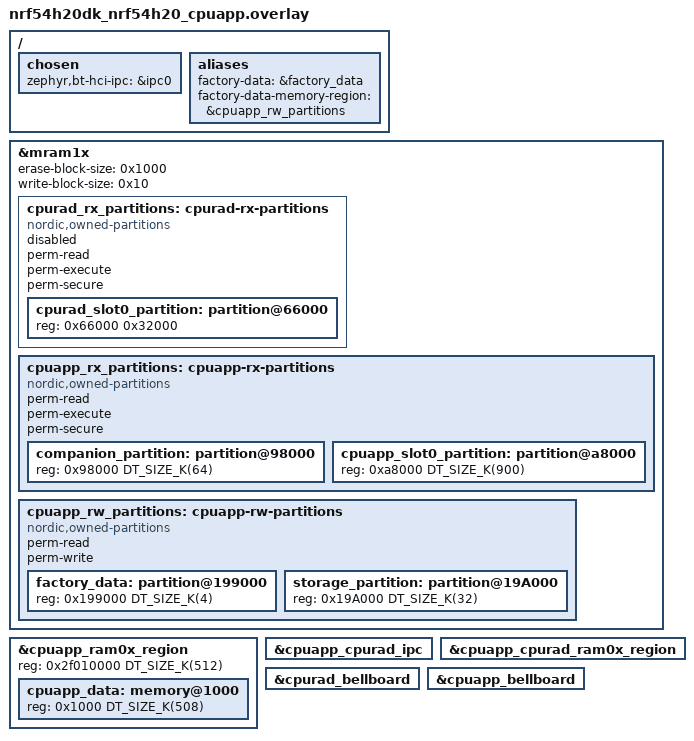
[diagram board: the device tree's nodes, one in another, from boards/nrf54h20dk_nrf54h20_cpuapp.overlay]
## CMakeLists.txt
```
#
# Copyright (c) 2021 Nordic Semiconductor ASA
#
# SPDX-License-Identifier: LicenseRef-Nordic-5-Clause
#

cmake_minimum_required(VERSION 3.20.0)

find_package(Zephyr HINTS $ENV{ZEPHYR_BASE})

project(matter-template)

# Enable GNU STD support.
include(${ZEPHYR_CONNECTEDHOMEIP_MODULE_DIR}/config/nrfconnect/app/enable-gnu-std.cmake)

# NORDIC SDK APP START

# Include all source files that are located in the Matter common directory.
include(${ZEPHYR_NRF_MODULE_DIR}/samples/matter/common/cmake/source_common.cmake)

# Include Data Model utils
include(${ZEPHYR_NRF_MODULE_DIR}/samples/matter/common/cmake/data_model.cmake)

target_include_directories(app PRIVATE
    src
    ${CONFIG_NCS_SAMPLE_MATTER_ZAP_FILES_PATH}
)

target_sources(app PRIVATE
    src/main.cpp
)

if("thread-platform" IN_LIST SNIPPET)
  target_sources(app PRIVATE 
    snippets/thread_platform/app_task.cpp
    snippets/thread_platform/zcl_callbacks.cpp
  )
  target_include_directories(app PRIVATE 
    snippets/thread_platform
  )
else()
  target_sources(app PRIVATE 
    src/app_task.cpp
  )
endif()

ncs_configure_data_model(
    ZAP_FILE ${CMAKE_CURRENT_SOURCE_DIR}/${CONFIG_NCS_SAMPLE_MATTER_ZAP_FILES_PATH}/template.zap
)
# NORDIC SDK APP END
```

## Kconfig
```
#
# Copyright (c) 2022 Nordic Semiconductor
#
# SPDX-License-Identifier: LicenseRef-Nordic-5-Clause
#
mainmenu "Matter nRF Connect Template Example Application"

# Sample configuration used for Thread networking
if OPENTHREAD

choice OPENTHREAD_NORDIC_LIBRARY_CONFIGURATION
	default OPENTHREAD_NORDIC_LIBRARY_MTD
endchoice

choice OPENTHREAD_DEVICE_TYPE
	default OPENTHREAD_MTD
endchoice

# SED with 0 dBm Thread TX output power for nRF54L15 tag
if BOARD_NRF54L15TAG

configdefault CHIP_ENABLE_ICD_SUPPORT
	default y

configdefault OPENTHREAD_DEFAULT_TX_POWER
	default 0

endif

endif # OPENTHREAD

configdefault CHIP_WIFI
	default y if SHIELD_NRF7002EB2

source "$(ZEPHYR_CONNECTEDHOMEIP_MODULE_DIR)/config/nrfconnect/chip-module/Kconfig.features"
source "$(ZEPHYR_CONNECTEDHOMEIP_MODULE_DIR)/config/nrfconnect/chip-module/Kconfig.defaults"
source "$(ZEPHYR_NRF_MODULE_DIR)/samples/matter/common/src/Kconfig"
source "Kconfig.zephyr"
```

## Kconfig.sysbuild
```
#
# Copyright (c) 2023 Nordic Semiconductor ASA
#
# SPDX-License-Identifier: LicenseRef-Nordic-5-Clause
#

# This config has to be enabled manually for variants with shields, because sysbuild does not support it.
config WIFI_NRF70
	default y if BOARD_NRF7002DK

#### Radio core selection
config NRF_DEFAULT_IPC_RADIO
	default y

# Enable IEEE802.15.4 serialization to network core
# This config automatically pulls in the `overlay-802154.conf` in the ipc_radio image
config NETCORE_IPC_RADIO_IEEE802154
	default y if SOC_SERIES_NRF53 && !WIFI_NRF70

# Enable Bluetooth serialization to network core
# This config automatically pulls in the `overlay-bt_hci_ipc.conf` in the ipc_radio image
config NETCORE_IPC_RADIO_BT_HCI_IPC
	default y if SOC_SERIES_NRF53

#### Bootloader
choice BOOTLOADER
	default BOOTLOADER_MCUBOOT if !BOARD_NRF21540DK
endchoice

if BOOTLOADER_MCUBOOT

#### DFU multi-image support
config DFU_MULTI_IMAGE_PACKAGE_BUILD
	default y

config DFU_MULTI_IMAGE_PACKAGE_APP
	default y

#### DFU network core configuration
if SOC_SERIES_NRF53

choice MCUBOOT_MODE
	default MCUBOOT_MODE_OVERWRITE_ONLY
endchoice

choice BOOT_SIGNATURE_TYPE
	default BOOT_SIGNATURE_TYPE_RSA
endchoice

config SECURE_BOOT_NETCORE
	default y

config NETCORE_APP_UPDATE
	default y

config DFU_MULTI_IMAGE_PACKAGE_NET
	default y

endif # SOC_SERIES_NRF53
endif # BOOTLOADER_MCUBOOT

# Store the Wi-Fi firmware patch on external flash by default for nRF5340 with nRF7002
if WIFI_NRF70 && SOC_NRF5340_CPUAPP

choice WIFI_PATCHES_EXT_FLASH_SUPPORT
	default WIFI_PATCHES_EXT_FLASH_STORE

endchoice

config DFU_MULTI_IMAGE_PACKAGE_WIFI_FW_PATCH
	default y

endif # WIFI_NRF70

#### Enable generating factory data
config MATTER_FACTORY_DATA_GENERATE
	default y if !BOARD_NRF21540DK

# Internal flash only for nRF54L15 tag with compression
if BOARD_NRF54L15TAG

choice MCUBOOT_MODE
	default MCUBOOT_MODE_OVERWRITE_ONLY
endchoice

config MCUBOOT_COMPRESSED_IMAGE_SUPPORT
	default y

endif

source "share/sysbuild/Kconfig"
```

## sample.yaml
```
sample:
  description: Matter Template sample
  name: Matter Template
common:
  tags:
    - sysbuild
    - ci_samples_matter
tests:
  sample.matter.template.debug:
    sysbuild: true
    build_only: true
    extra_args:
      - CONFIG_NCS_SAMPLE_MATTER_OPERATIONAL_KEYS_MIGRATION_TO_ITS=y
    integration_platforms:
      - nrf52840dk/nrf52840
      - nrf5340dk/nrf5340/cpuapp
      - nrf54l15dk/nrf54l15/cpuapp
      - nrf54l15dk/nrf54l10/cpuapp
      - nrf54l15tag/nrf54l15/cpuapp
      - nrf54lm20dk/nrf54lm20b/cpuapp
      - nrf54lm20dk/nrf54lm20a/cpuapp
    platform_allow:
      - nrf52840dk/nrf52840
      - nrf5340dk/nrf5340/cpuapp
      - nrf54l15dk/nrf54l15/cpuapp
      - nrf54l15dk/nrf54l15/cpuapp/ns
      - nrf54l15dk/nrf54l10/cpuapp
      - nrf54l15tag/nrf54l15/cpuapp
      - nrf54lm20dk/nrf54lm20b/cpuapp
      - nrf54lm20dk/nrf54lm20a/cpuapp
  sample.matter.template.nrf7002eb2.debug:
    sysbuild: true
    build_only: true
    extra_args:
      - template_SHIELD=nrf7002eb2
      - SB_CONFIG_WIFI_NRF70=y
    integration_platforms:
      - nrf54lm20dk/nrf54lm20b/cpuapp
      - nrf54lm20dk/nrf54lm20a/cpuapp
    platform_allow:
      - nrf54lm20dk/nrf54lm20b/cpuapp
      - nrf54lm20dk/nrf54lm20a/cpuapp
  sample.matter.template.release:
    sysbuild: true
    build_only: true
    extra_args:
      - FILE_SUFFIX=release
      - CONFIG_NCS_SAMPLE_MATTER_OPERATIONAL_KEYS_MIGRATION_TO_ITS=y
    integration_platforms:
      - nrf52840dk/nrf52840
      - nrf5340dk/nrf5340/cpuapp
      - nrf54l15dk/nrf54l15/cpuapp
      - nrf54l15dk/nrf54l10/cpuapp
      - nrf54l15tag/nrf54l15/cpuapp
      - nrf54lm20dk/nrf54lm20b/cpuapp
      - nrf54lm20dk/nrf54lm20a/cpuapp
    platform_allow:
      - nrf52840dk/nrf52840
      - nrf5340dk/nrf5340/cpuapp
      - nrf54l15dk/nrf54l15/cpuapp
      - nrf54l15dk/nrf54l10/cpuapp
      - nrf54l15tag/nrf54l15/cpuapp
      - nrf54lm20dk/nrf54lm20b/cpuapp
      - nrf54lm20dk/nrf54lm20a/cpuapp
  sample.matter.template.nrf7002eb2.release:
    sysbuild: true
    build_only: true
    extra_args:
      - FILE_SUFFIX=release
      - template_SHIELD=nrf7002eb2
      - SB_CONFIG_WIFI_NRF70=y
    integration_platforms:
      - nrf54lm20dk/nrf54lm20b/cpuapp
      - nrf54lm20dk/nrf54lm20a/cpuapp
    platform_allow:
      - nrf54lm20dk/nrf54lm20b/cpuapp
      - nrf54lm20dk/nrf54lm20a/cpuapp
  sample.matter.template.smp_dfu:
    sysbuild: true
    build_only: true
    extra_args:
      - CONFIG_CHIP_DFU_OVER_BT_SMP=y
      - CONFIG_NCS_SAMPLE_MATTER_OPERATIONAL_KEYS_MIGRATION_TO_ITS=y
    integration_platforms:
      - nrf54l15dk/nrf54l15/cpuapp
      - nrf54l15dk/nrf54l10/cpuapp
      - nrf54l15tag/nrf54l15/cpuapp
      - nrf54lm20dk/nrf54lm20b/cpuapp
      - nrf54lm20dk/nrf54lm20a/cpuapp
    platform_allow:
      - nrf52840dk/nrf52840
      - nrf5340dk/nrf5340/cpuapp
      - nrf54l15dk/nrf54l15/cpuapp
      - nrf54l15dk/nrf54l10/cpuapp
      - nrf54l15tag/nrf54l15/cpuapp
      - nrf54lm20dk/nrf54lm20b/cpuapp
      - nrf54lm20dk/nrf54lm20a/cpuapp
  sample.matter.template.tfm:
    sysbuild: true
    build_only: true
    extra_args:
      - FILE_SUFFIX=tfm
      - CONFIG_CHIP_DFU_OVER_BT_SMP=y
    integration_platforms:
      - nrf54l15dk/nrf54l15/cpuapp/ns
    platform_allow:
      - nrf54l15dk/nrf54l15/cpuapp/ns
  sample.matter.template.nrf7002eb2.smp_dfu:
    sysbuild: true
    build_only: true
    extra_args:
      - CONFIG_CHIP_DFU_OVER_BT_SMP=y
      - template_SHIELD=nrf7002eb2
      - SB_CONFIG_WIFI_NRF70=y
    integration_platforms:
      - nrf54lm20dk/nrf54lm20b/cpuapp
      - nrf54lm20dk/nrf54lm20a/cpuapp
    platform_allow:
      - nrf54lm20dk/nrf54lm20b/cpuapp
      - nrf54lm20dk/nrf54lm20a/cpuapp
  sample.matter.template.release.internal:
    sysbuild: true
    build_only: true
    extra_args:
      - FILE_SUFFIX=internal
      - template_EXTRA_CONF_FILE=prj_release.conf
    integration_platforms:
      - nrf54l15dk/nrf54l15/cpuapp
      - nrf54lm20dk/nrf54lm20b/cpuapp
      - nrf54lm20dk/nrf54lm20a/cpuapp
    platform_allow:
      - nrf54l15dk/nrf54l15/cpuapp
      - nrf54lm20dk/nrf54lm20b/cpuapp
      - nrf54lm20dk/nrf54lm20a/cpuapp
  sample.matter.template.nrf7002eb2.release.internal:
    sysbuild: true
    build_only: true
    extra_args:
      - FILE_SUFFIX=internal
      - template_EXTRA_CONF_FILE=prj_release.conf
      - template_SHIELD=nrf7002eb2
      - SB_CONFIG_WIFI_NRF70=y
    integration_platforms:
      - nrf54lm20dk/nrf54lm20b/cpuapp
      - nrf54lm20dk/nrf54lm20a/cpuapp
    platform_allow:
      - nrf54lm20dk/nrf54lm20b/cpuapp
      - nrf54lm20dk/nrf54lm20a/cpuapp
  sample.matter.template.release.internal.smp_dfu:
    sysbuild: true
    build_only: true
    extra_args:
      - FILE_SUFFIX=internal
      - CONFIG_CHIP_DFU_OVER_BT_SMP=y
      - template_EXTRA_CONF_FILE=prj_release.conf
    integration_platforms:
      - nrf54l15dk/nrf54l15/cpuapp
      - nrf54lm20dk/nrf54lm20b/cpuapp
      - nrf54lm20dk/nrf54lm20a/cpuapp
    platform_allow:
      - nrf54l15dk/nrf54l15/cpuapp
      - nrf54lm20dk/nrf54lm20b/cpuapp
      - nrf54lm20dk/nrf54lm20a/cpuapp
  sample.matter.template.nrf7002eb2.release.internal.smp_dfu:
    sysbuild: true
    build_only: true
    extra_args:
      - FILE_SUFFIX=internal
      - CONFIG_CHIP_DFU_OVER_BT_SMP=y
      - template_EXTRA_CONF_FILE=prj_release.conf
      - template_SHIELD=nrf7002eb2
      - SB_CONFIG_WIFI_NRF70=y
    integration_platforms:
      - nrf54lm20dk/nrf54lm20b/cpuapp
      - nrf54lm20dk/nrf54lm20a/cpuapp
    platform_allow:
      - nrf54lm20dk/nrf54lm20b/cpuapp
      - nrf54lm20dk/nrf54lm20a/cpuapp
  sample.matter.template.cc3xx_backend:
    sysbuild: true
    build_only: true
    extra_args:
      - CONFIG_PSA_CRYPTO_DRIVER_CC3XX=y
    integration_platforms:
      - nrf52840dk/nrf52840
      - nrf5340dk/nrf5340/cpuapp
    platform_allow:
      - nrf52840dk/nrf52840
      - nrf5340dk/nrf5340/cpuapp
  sample.matter.template.smp_dfu.old_ec:
    sysbuild: true
    build_only: true
    extra_args:
      - CONFIG_CHIP_DFU_OVER_BT_SMP=y
      - SB_CONFIG_BOOT_SIGNATURE_TYPE_RSA=y
      - CONFIG_SETTINGS_ZMS_LEGACY=y
    integration_platforms:
      - nrf54l15dk/nrf54l15/cpuapp
    platform_allow:
      - nrf54l15dk/nrf54l15/cpuapp
  sample.matter.template.certification:
    sysbuild: true
    build_only: true
    extra_args:
      - CONFIG_NCS_SAMPLE_MATTER_CERTIFICATION=y
      - OVERLAY_CONFIG="../common/src/certification/thread_platform/overlay-thread_platform.conf"
      - template_SNIPPET="matter-diagnostic-logs;matter-debug"
    integration_platforms:
      - nrf52840dk/nrf52840
      - nrf5340dk/nrf5340/cpuapp
      - nrf54l15dk/nrf54l15/cpuapp
      - nrf54lm20dk/nrf54lm20b/cpuapp
      - nrf54lm20dk/nrf54lm20a/cpuapp
    platform_allow:
      - nrf52840dk/nrf52840
      - nrf5340dk/nrf5340/cpuapp
      - nrf54l15dk/nrf54l15/cpuapp
      - nrf54lm20dk/nrf54lm20b/cpuapp
      - nrf54lm20dk/nrf54lm20a/cpuapp
```

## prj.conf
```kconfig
#
# Copyright (c) 2021 Nordic Semiconductor ASA
#
# SPDX-License-Identifier: LicenseRef-Nordic-5-Clause
#

# This sample uses Kconfig.defaults to set options common for all
# samples. This file should contain only options specific for this sample
# or overrides of default values.

# Enable CHIP
CONFIG_CHIP=y
CONFIG_CHIP_PROJECT_CONFIG="src/chip_project_config.h"

# Configure ZAP file name
CONFIG_NCS_SAMPLE_MATTER_ZAP_FILE_NAME="template.zap"

# 32768 == 0x8000 (example Product ID added temporaly,
# but it must be changed with proper PID from the list:
# https://github.com/project-chip/connectedhomeip/blob/482e6fd03196a6de45465a90003947ef4b86e0b1/docs/examples/discussion/PID_allocation_for_example_apps.md)
CONFIG_CHIP_DEVICE_PRODUCT_ID=32768
CONFIG_STD_CPP17=y

# Enable Matter pairing automatically on application start.
CONFIG_CHIP_ENABLE_PAIRING_AUTOSTART=y

# Enable Matter extended announcement and increase duration to 1 hour.
CONFIG_CHIP_BLE_EXT_ADVERTISING=y
CONFIG_CHIP_BLE_ADVERTISING_DURATION=60

# Add support for LEDs and buttons on Nordic development kits
CONFIG_DK_LIBRARY=y

# Bluetooth Low Energy configuration
CONFIG_BT_DEVICE_NAME="MatterTemplate"

# Other settings
CONFIG_THREAD_NAME=y
CONFIG_MPU_STACK_GUARD=y
CONFIG_RESET_ON_FATAL_ERROR=n
CONFIG_CHIP_LIB_SHELL=y
CONFIG_NCS_SAMPLE_MATTER_TEST_SHELL=y

# Disable NFC commissioning
CONFIG_CHIP_NFC_ONBOARDING_PAYLOAD=n

# Reduce application size
CONFIG_USE_SEGGER_RTT=n

# Enable Factory Data feature
CONFIG_CHIP_FACTORY_DATA=y
CONFIG_CHIP_FACTORY_DATA_BUILD=y
```

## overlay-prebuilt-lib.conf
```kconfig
# Use the prebuilt Matter stack library from the Matter module lib/ directory.
CONFIG_CHIP_USE_PREBUILT_LIB=y
```

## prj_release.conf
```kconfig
#
# Copyright (c) 2021 Nordic Semiconductor ASA
#
# SPDX-License-Identifier: LicenseRef-Nordic-5-Clause
#

# This sample uses Kconfig.defaults to set options common for all
# samples. This file should contain only options specific for this sample
# or overrides of default values.

# Enable CHIP
CONFIG_CHIP=y
CONFIG_CHIP_PROJECT_CONFIG="src/chip_project_config.h"
# 32768 == 0x8000 (example Product ID added temporaly,
# but it must be changed with proper PID from the list:
# https://github.com/project-chip/connectedhomeip/blob/482e6fd03196a6de45465a90003947ef4b86e0b1/docs/examples/discussion/PID_allocation_for_example_apps.md)
CONFIG_CHIP_DEVICE_PRODUCT_ID=32768
CONFIG_STD_CPP17=y

# Enable Matter pairing automatically on application start.
CONFIG_CHIP_ENABLE_PAIRING_AUTOSTART=y

# Enable Matter extended announcement and increase duration to 1 hour.
CONFIG_CHIP_BLE_EXT_ADVERTISING=y
CONFIG_CHIP_BLE_ADVERTISING_DURATION=60

# Add support for LEDs and buttons on Nordic development kits
CONFIG_DK_LIBRARY=y

# Bluetooth Low Energy configuration
CONFIG_BT_DEVICE_NAME="MatterTemplate"

# Enable system reset on fatal error
CONFIG_RESET_ON_FATAL_ERROR=y

# Disable all debug features
CONFIG_USE_SEGGER_RTT=n
CONFIG_SHELL=n
CONFIG_OPENTHREAD_SHELL=n
CONFIG_CHIP_LIB_SHELL=n
CONFIG_CONSOLE=n
CONFIG_UART_CONSOLE=n
CONFIG_SERIAL=n
CONFIG_LOG=n
CONFIG_LOG_MODE_MINIMAL=n
CONFIG_ASSERT_VERBOSE=n
CONFIG_ASSERT_NO_FILE_INFO=y
CONFIG_PRINTK=n
CONFIG_PRINTK_SYNC=n
CONFIG_THREAD_NAME=n
CONFIG_BOOT_BANNER=n

# Disable NFC commissioning
CONFIG_CHIP_NFC_COMMISSIONING=n

# Enable Factory Data feature
CONFIG_CHIP_FACTORY_DATA=y
CONFIG_CHIP_FACTORY_DATA_BUILD=y

# Enable Watchdog
CONFIG_NCS_MATTER_WATCHDOG=y

# Enable LTO to decrease the flash usage.
CONFIG_LTO=y
CONFIG_ISR_TABLES_LOCAL_DECLARATION=y
```

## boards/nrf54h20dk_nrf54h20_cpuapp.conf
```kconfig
#
# Copyright (c) 2024 Nordic Semiconductor ASA
#
# SPDX-License-Identifier: LicenseRef-Nordic-5-Clause
#

# TODO: Workaround to be removed once DFU and external flash will be supported on nRF54H20.
CONFIG_CHIP_QSPI_NOR=n

CONFIG_MPU_STACK_GUARD=n

# TODO: Enable PSA crypto once it is available
CONFIG_CHIP_CRYPTO_PSA=n
CONFIG_MBEDTLS_CIPHER_PADDING_PKCS7=y
CONFIG_MBEDTLS_CIPHER_MODE_CBC=y

# TODO: Enable factory data once it is available
CONFIG_CHIP_FACTORY_DATA=n

# TODO: Workaround to be removed once Zephyr's CONFIG_FPROTECT is supported on nRF54H20.
CONFIG_CHIP_FACTORY_DATA_WRITE_PROTECT=n

# Set SUIT template paths
CONFIG_SUIT_ENVELOPE_TEMPLATE="../common/suit_templates/app_envelope.yaml.jinja2"
```

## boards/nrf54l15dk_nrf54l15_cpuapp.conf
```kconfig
#
# Copyright (c) 2024 Nordic Semiconductor ASA
#
# SPDX-License-Identifier: LicenseRef-Nordic-5-Clause
#

# Multirole is the only currently supported role by SoftDevice.
CONFIG_BT_LL_SOFTDEVICE_MULTIROLE=y

# ZMS cache optimization
CONFIG_ZMS_LOOKUP_CACHE=y
CONFIG_ZMS_LOOKUP_CACHE_SIZE=512
CONFIG_ZMS_LOOKUP_CACHE_FOR_SETTINGS=y

# Workaround required as Zephyr L2 implies usage of NVS backend for settings.
# It should be removed once the proper fix will be applied in Zephyr.
CONFIG_NVS=n

# Enable KMU support
CONFIG_OPENTHREAD_PSA_NVM_BACKEND_KMU=y 
CONFIG_CHIP_STORE_KEYS_IN_KMU=y
```

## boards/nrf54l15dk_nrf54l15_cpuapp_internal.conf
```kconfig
#
# Copyright (c) 2024 Nordic Semiconductor ASA
#
# SPDX-License-Identifier: LicenseRef-Nordic-5-Clause
#

# Multirole is the only currently supported role by SoftDevice.
CONFIG_BT_LL_SOFTDEVICE_MULTIROLE=y

# ZMS cache optimization
CONFIG_ZMS_LOOKUP_CACHE=y
CONFIG_ZMS_LOOKUP_CACHE_SIZE=512
CONFIG_ZMS_LOOKUP_CACHE_FOR_SETTINGS=y

# Workaround required as Zephyr L2 implies usage of NVS backend for settings.
# It should be removed once the proper fix will be applied in Zephyr.
CONFIG_NVS=n

# Disable SPI
CONFIG_CHIP_SPI_NOR=n

# Enable Watchdog
CONFIG_NCS_MATTER_WATCHDOG=y

# Enable LTO to decrease the flash usage.
CONFIG_LTO=y
CONFIG_ISR_TABLES_LOCAL_DECLARATION=y
```

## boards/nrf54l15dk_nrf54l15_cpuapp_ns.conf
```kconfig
#
# Copyright (c) 2024 Nordic Semiconductor ASA
#
# SPDX-License-Identifier: LicenseRef-Nordic-5-Clause
#

# Multirole is the only currently supported role by SoftDevice.
CONFIG_BT_LL_SOFTDEVICE_MULTIROLE=y

# TODO: Workaround to be removed once Zephyr's CONFIG_FPROTECT is supported on nRF54L_ns
CONFIG_CHIP_FACTORY_DATA_WRITE_PROTECT=n

# nRF54L15 requires bigger stack sizes than nRF52/nRF53 families
CONFIG_CHIP_MALLOC_SYS_HEAP_SIZE=10240
CONFIG_MPSL_WORK_STACK_SIZE=2048

# Set the ZMS sector count to match the settings partition size that is 40 kB for this application.
CONFIG_SETTINGS_ZMS_SECTOR_COUNT=10
# Workaround required as Zephyr L2 implies usage of NVS backend for settings.
# It should be removed once the proper fix will be applied in Zephyr.
CONFIG_NVS=n

# Disable unused Protected Storage to save memory.
CONFIG_TFM_PARTITION_PROTECTED_STORAGE=n
# Disable ITS to save memory.
CONFIG_TFM_PARTITION_INTERNAL_TRUSTED_STORAGE=n
CONFIG_MBEDTLS_PSA_CRYPTO_STORAGE_C=n
# Switch to TFM_SFN to save memory. This is possible only for TFM isolation level 1.
CONFIG_TFM_SFN=y
# Disable logs from TFM
CONFIG_TFM_LOG_LEVEL_SILENCE=y
```

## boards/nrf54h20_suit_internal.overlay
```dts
/* Copyright (c) 2024 Nordic Semiconductor ASA
 *
 * SPDX-License-Identifier: LicenseRef-Nordic-5-Clause
 */

/* Reorganize partitions for SUIT */
/delete-node/ &cpuapp_rx_partitions;
/delete-node/ &cpuapp_rw_partitions;

&mram1x {
	erase-block-size = < 0x1000 >;
	write-block-size = < 0x10 >;

	cpurad_rx_partitions: cpurad-rx-partitions {
		compatible = "nordic,owned-partitions", "fixed-partitions";
		status = "disabled";
		perm-read;
		perm-execute;
		perm-secure;
		#address-cells = < 0x1 >;
		#size-cells = < 0x1 >;
		cpurad_slot0_partition: partition@66000 {
			reg = < 0x66000 0x32000 >;
		};
	};

	cpuapp_rx_partitions: cpuapp-rx-partitions {
		compatible = "nordic,owned-partitions", "fixed-partitions";
		status = "okay";
		perm-read;
		perm-execute;
		perm-secure;
		#address-cells = <1>;
		#size-cells = <1>;

		cpuapp_slot0_partition: partition@98000 {
			reg = <0x98000 DT_SIZE_K(656)>;
		};
	};

	cpuapp_rw_partitions: cpuapp-rw-partitions {
		compatible = "nordic,owned-partitions", "fixed-partitions";
		status = "okay";
		perm-read;
		perm-write;
		#address-cells = < 0x1 >;
		#size-cells = < 0x1 >;

		storage_partition: partition@13C000 {
			reg = < 0x13C000 DT_SIZE_K(32) >;
		};

		factory_data: partition@144000 {
			reg = < 0x144000 DT_SIZE_K(4) >;
		};

		dfu_partition: partition@145000 {
			reg = < 0x145000 DT_SIZE_K(656) >;
		};
	};
};

/* Communication between Application Core and Secure domain for SUIT */
&cpusec_cpuapp_ipc {
	status = "okay";
};
&cpusec_bellboard {
	status = "okay";
};
```

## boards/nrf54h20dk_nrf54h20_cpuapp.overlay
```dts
/*
 * Copyright (c) 2024 Nordic Semiconductor ASA
 *
 * SPDX-License-Identifier: LicenseRef-Nordic-5-Clause
 */

/ {
	chosen {
		/* prepare IPC to HCI Radio core */
		zephyr,bt-hci-ipc = &ipc0;
	};

	aliases {
		factory-data = &factory_data;
		factory-data-memory-region = &cpuapp_rw_partitions;
	};
};

/**************************************************************
Redefine MRAM memory (Partitions)
**************************************************************/
/* We need to redefine partitions to meet Matter requirements */
/delete-node/ &cpuapp_rx_partitions;
/delete-node/ &cpuapp_rw_partitions;
/delete-node/ &cpurad_rx_partitions;
/delete-node/ &cpuppr_vpr;
/delete-node/ &cpuapp_cpuppr_ipc;

&mram1x {
	erase-block-size = < 0x1000 >;
	write-block-size = < 0x10 >;

	cpurad_rx_partitions: cpurad-rx-partitions {
		compatible = "nordic,owned-partitions", "fixed-partitions";
		status = "disabled";
		perm-read;
		perm-execute;
		perm-secure;
		#address-cells = < 0x1 >;
		#size-cells = < 0x1 >;
		cpurad_slot0_partition: partition@66000 {
			reg = < 0x66000 0x32000 >;
		};
	};

	cpuapp_rx_partitions: cpuapp-rx-partitions {
		compatible = "nordic,owned-partitions", "fixed-partitions";
		status = "okay";
		perm-read;
		perm-execute;
		perm-secure;
		#address-cells = <1>;
		#size-cells = <1>;

		companion_partition: partition@98000 {
			reg = <0x98000 DT_SIZE_K(64)>;
		};

		cpuapp_slot0_partition: partition@a8000 {
			reg = <0xa8000 DT_SIZE_K(900)>;
		};

	};

	cpuapp_rw_partitions: cpuapp-rw-partitions {
		compatible = "nordic,owned-partitions", "fixed-partitions";
		status = "okay";
		perm-read;
		perm-write;
		#address-cells = < 0x1 >;
		#size-cells = < 0x1 >;

		factory_data: partition@199000 {
			reg = < 0x199000 DT_SIZE_K(4) >;
		};

		storage_partition: partition@19A000 {
			reg = < 0x19A000 DT_SIZE_K(32) >;
		};
	};
};

/**************************************************************
Redefine RAM memory.
**************************************************************/
&cpuapp_ram0x_region{
	status = "okay";
	reg = <0x2f010000 DT_SIZE_K(512)>;
	ranges = <0x0 0x2f010000 0x6e000>;
	cpuapp_data: memory@1000 {
		reg = <0x1000 DT_SIZE_K(508)>;
	};
};

/**************************************************************
Enable required peripherals
**************************************************************/
/* Communication between Application and Radio Cores */
ipc0: &cpuapp_cpurad_ipc {
	status = "okay";
};
&cpuapp_cpurad_ram0x_region {
	status = "okay";
};
&cpurad_bellboard {
	status = "okay";
};
&cpuapp_bellboard {
	status = "okay";
};
```

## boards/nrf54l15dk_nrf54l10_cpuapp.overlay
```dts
/*
 * Copyright (c) 2024 Nordic Semiconductor ASA
 *
 * SPDX-License-Identifier: LicenseRef-Nordic-5-Clause
 */

#include <samples/matter/nrf54l10_partitions.dtsi>

/ {
	aliases {
		/* Use watchdog wdt31 as the application watchdog */
		watchdog0 = &wdt31;
	};
};

&wdt31 {
	status = "okay";
};
```

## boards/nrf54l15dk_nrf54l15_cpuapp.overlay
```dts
/*
 * Copyright (c) 2024 Nordic Semiconductor ASA
 *
 * SPDX-License-Identifier: LicenseRef-Nordic-5-Clause
 */

#include <samples/matter/nrf54l15_partitions.dtsi>

/ {
	aliases {
		/* Use watchdog wdt31 as the application watchdog */
		watchdog0 = &wdt31;
	};
};

&wdt31 {
	status = "okay";
};
```

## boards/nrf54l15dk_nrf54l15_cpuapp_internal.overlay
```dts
/*
 * Copyright (c) 2024 Nordic Semiconductor ASA
 *
 * SPDX-License-Identifier: LicenseRef-Nordic-5-Clause
 */

#include <samples/matter/nrf54l15_internal_partitions.dtsi>

/ {
	aliases {
		/* Use watchdog wdt31 as the application watchdog */
		watchdog0 = &wdt31;
	};
};

&wdt31 {
	status = "okay";
};
```

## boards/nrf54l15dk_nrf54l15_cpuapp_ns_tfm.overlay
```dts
/*
 * Copyright (c) 2025 Nordic Semiconductor ASA
 *
 * SPDX-License-Identifier: LicenseRef-Nordic-5-Clause
 */

#include <samples/matter/nrf54l15_cpuapp_tfm_base_partitions.dtsi>
#include <samples/matter/nrf54l15_cpuapp_tfm_application_partitions.dtsi>

/ {
	aliases {
		/* Use watchdog wdt31 as the application watchdog */
		watchdog0 = &wdt31;
	};

	chosen {
		nordic,pm-ext-flash = &mx25r64;
	};
};

&mx25r64 {
	status = "okay";
};

&wdt31 {
	status = "okay";
};

/* Change IRQ ids to handle button interrupts.
 * The default values for nRF54L15 are 219 and 269,
 * but with TF-M they are reserved for the secure domain
 * (218 and 268 are reserved for the non-secure domain).
 */
&gpiote20 {
	interrupts = <218 NRF_DEFAULT_IRQ_PRIORITY>;
};

&gpiote30 {
	interrupts = <268 NRF_DEFAULT_IRQ_PRIORITY>;
};
```

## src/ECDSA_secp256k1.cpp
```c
/*
 * Copyright (c) 2024 Nordic Semiconductor ASA
 *
 * SPDX-License-Identifier: LicenseRef-Nordic-5-Clause
 */

#include <psa/crypto.h>

#include "ECDSA_secp256k1.h"

#include <zephyr/logging/log.h>

LOG_MODULE_DECLARE(app, CONFIG_CHIP_APP_LOG_LEVEL);

namespace ECDSA_Test
{

psa_status_t K256Keypair::Initialize()
{
	if (mInitialized) {
		return PSA_ERROR_BAD_STATE;
	}

	psa_status_t status = PSA_SUCCESS;
	psa_key_attributes_t attributes = PSA_KEY_ATTRIBUTES_INIT;
	size_t publicKeyLength = 0;

	// Type based on ECC with the elliptic curve SECP256k1
	psa_set_key_type(&attributes, PSA_KEY_TYPE_ECC_KEY_PAIR(PSA_ECC_FAMILY_SECP_K1));
	psa_set_key_bits(&attributes, kK256_PrivateKeyLength * 8);
	psa_set_key_algorithm(&attributes, PSA_ALG_ECDSA(PSA_ALG_SHA_256));
#ifdef CONFIG_ECDSA_SECP256K1_TEST_ALLOW_KEY_EXPORT
	psa_set_key_usage_flags(&attributes, PSA_KEY_USAGE_EXPORT | PSA_KEY_USAGE_SIGN_MESSAGE);
#else
	psa_set_key_usage_flags(&attributes, PSA_KEY_USAGE_SIGN_MESSAGE);
#endif
	psa_set_key_lifetime(&attributes, PSA_KEY_LIFETIME_VOLATILE);

	status = psa_generate_key(&attributes, &mSecretKeyId);
	if (PSA_SUCCESS != status) {
		psa_destroy_key(mSecretKeyId);
		psa_reset_key_attributes(&attributes);
		return status;
	}

	status = psa_export_public_key(mSecretKeyId, mPublicKey, mPublicKeySize, &publicKeyLength);

	if (PSA_SUCCESS != status) {
		psa_destroy_key(mSecretKeyId);
		psa_reset_key_attributes(&attributes);
		return status;
	}

	if (publicKeyLength != mPublicKeySize) {
		return PSA_ERROR_DATA_INVALID;
	}

	mInitialized = true;

	return PSA_SUCCESS;
}

psa_status_t K256Keypair::Import(const uint8_t *privKey, size_t privKeyLen, const uint8_t *pubKey, size_t pubKeyLen)
{
	if (!privKey || privKeyLen == 0 || !pubKey || pubKeyLen == 0) {
		return PSA_ERROR_INVALID_ARGUMENT;
	}

	psa_status_t status = PSA_SUCCESS;
	psa_key_attributes_t attributes = PSA_KEY_ATTRIBUTES_INIT;

	if (mInitialized) {
		psa_destroy_key(mSecretKeyId);
		psa_reset_key_attributes(&attributes);
	}

	// Type based on ECC with the elliptic curve SECP256k1
	psa_set_key_type(&attributes, PSA_KEY_TYPE_ECC_KEY_PAIR(PSA_ECC_FAMILY_SECP_K1));
	psa_set_key_bits(&attributes, kK256_PrivateKeyLength * 8);
	psa_set_key_algorithm(&attributes, PSA_ALG_ECDSA(PSA_ALG_SHA_256));
#ifdef CONFIG_ECDSA_SECP256K1_TEST_ALLOW_KEY_EXPORT
	psa_set_key_usage_flags(&attributes, PSA_KEY_USAGE_EXPORT | PSA_KEY_USAGE_SIGN_MESSAGE);
#else
	psa_set_key_usage_flags(&attributes, PSA_KEY_USAGE_SIGN_MESSAGE);
#endif
	psa_set_key_lifetime(&attributes, PSA_KEY_LIFETIME_VOLATILE);

	status = psa_import_key(&attributes, privKey, privKeyLen, &mSecretKeyId);
	if (PSA_SUCCESS != status) {
		psa_destroy_key(mSecretKeyId);
		psa_reset_key_attributes(&attributes);
		return status;
	}

	if (mPublicKeySize != pubKeyLen) {
		return PSA_ERROR_DATA_INVALID;
	}

	memcpy(mPublicKey, pubKey, mPublicKeySize);

	mInitialized = true;

	return PSA_SUCCESS;
}

psa_status_t K256Keypair::Export(uint8_t *privKey, size_t &privKeyLen)
{
	if (!mInitialized || !privKey || privKeyLen == 0) {
		return PSA_ERROR_INVALID_ARGUMENT;
	}
	psa_status_t status = PSA_SUCCESS;
	size_t privateKeyLength = 0;

	status = psa_export_key(mSecretKeyId, privKey, privKeyLen, &privateKeyLength);
	if (PSA_SUCCESS != status) {
		return status;
	}

	privKeyLen = privateKeyLength;

	return PSA_SUCCESS;
}

psa_status_t K256Keypair::ECDSA_sign_msg(const uint8_t *msg, const size_t msgLength, K256ECDSASignature &outSignature)
{
	if (!mInitialized || !msg || msgLength == 0) {
		return false;
	}

	psa_status_t status = PSA_SUCCESS;
	size_t outputLen = 0;

	status = psa_sign_message(mSecretKeyId, PSA_ALG_ECDSA(PSA_ALG_SHA_256), msg, msgLength, outSignature.data,
				  outSignature.size, &outputLen);
	if (status != PSA_SUCCESS || outputLen != kMax_ECDSA_Signature_Length) {
		return status;
	}

	outSignature.size = outputLen;

	return PSA_SUCCESS;
}

psa_status_t K256Keypair::ECDSA_validate_msg_signature(const uint8_t *msg, const size_t msgLength,
					       const K256ECDSASignature &signature, K256PublicKey &pubKey)
{
	if (!msg || msgLength == 0) {
		return PSA_ERROR_INVALID_ARGUMENT;
	}

	psa_status_t status = PSA_SUCCESS;
	psa_key_id_t keyId = 0;
	psa_key_attributes_t attributes = PSA_KEY_ATTRIBUTES_INIT;

	psa_set_key_type(&attributes, PSA_KEY_TYPE_ECC_PUBLIC_KEY(PSA_ECC_FAMILY_SECP_K1));
	psa_set_key_algorithm(&attributes, PSA_ALG_ECDSA(PSA_ALG_SHA_256));
	psa_set_key_usage_flags(&attributes, PSA_KEY_USAGE_VERIFY_MESSAGE);

	status = psa_import_key(&attributes, pubKey, sizeof(pubKey), &keyId);

	if (status == PSA_SUCCESS) {
		status = psa_verify_message(keyId, PSA_ALG_ECDSA(PSA_ALG_SHA_256), msg, msgLength, signature.data,
					    signature.size);
	}

	psa_destroy_key(keyId);
	psa_reset_key_attributes(&attributes);
	return status;
}

} // namespace ECDSA_Test
```

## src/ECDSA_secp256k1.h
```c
/*
 * Copyright (c) 2024 Nordic Semiconductor ASA
 *
 * SPDX-License-Identifier: LicenseRef-Nordic-5-Clause
 */

#pragma once

#include <psa/crypto.h>

namespace ECDSA_Test
{
constexpr uint8_t kTestMessage[] = { 'E', 'C', 'D', 'S', 'A', '_', 's', 'e', 'c', 'p',
				     '2', '5', '6', 'k', '1', '_', 'T', 'E', 'S', 'T' };
constexpr uint8_t kTestPrivKey[] = { 0x9d, 0xe4, 0x9b, 0xe4, 0x35, 0x8c, 0x04, 0x99, 0x01, 0x34, 0xb7,
				     0xe8, 0xa0, 0xf0, 0x18, 0x35, 0x37, 0x7d, 0xd2, 0x77, 0xb1, 0x5a,
				     0xb1, 0x9b, 0xbc, 0xf7, 0xeb, 0x7b, 0xe7, 0xde, 0x5e, 0x18 };
constexpr uint8_t kTestPubKey[] = { 0x04, 0x20, 0xe6, 0x6d, 0x1b, 0xbc, 0x5e, 0x14, 0xb5, 0xe9, 0x4d, 0xf5, 0xf7,
				    0x58, 0x25, 0xfb, 0x44, 0x60, 0xc6, 0x5b, 0x8a, 0x9b, 0xcc, 0xae, 0x6a, 0x02,
				    0xce, 0xdf, 0xf6, 0xf9, 0xcc, 0x08, 0xf3, 0xda, 0x39, 0x3f, 0xb5, 0x8f, 0x09,
				    0x11, 0x0c, 0x7e, 0xcb, 0xcb, 0xd5, 0x95, 0x24, 0x51, 0x01, 0xa7, 0x92, 0x1d,
				    0x01, 0x0f, 0xdf, 0xa4, 0xe1, 0xe8, 0x68, 0x21, 0x76, 0xf5, 0xfe, 0xaa, 0x27 };

constexpr auto kK256_PublicKeyLength = 2 * 32 + 1;
constexpr auto kK256_PrivateKeyLength = 32;
constexpr auto kMax_ECDSA_Signature_Length = 2 * 32;

struct K256ECDSASignature {
	uint8_t data[kMax_ECDSA_Signature_Length];
	size_t size = kMax_ECDSA_Signature_Length;
};

using K256PublicKey = uint8_t[kK256_PublicKeyLength];

struct k256SerializedKeyPair;

class K256Keypair {
public:
	K256Keypair() {}

	psa_status_t Initialize();
	psa_status_t Import(const uint8_t *privKey, size_t privKeyLen, const uint8_t *pubKey, size_t pubKeyLen);
	psa_status_t Export(uint8_t *privKey, size_t &privKeyLen);

	psa_status_t ECDSA_sign_msg(const uint8_t *msg, const size_t msgLength, K256ECDSASignature &outSignature);
	psa_status_t ECDSA_validate_msg_signature(const uint8_t *msg, const size_t msg_length,
						  const K256ECDSASignature &signature, K256PublicKey &pubKey);

	uint8_t *GetPubKey() { return mPublicKey; }
	size_t GetPubKeyLen() { return mPublicKeySize; }

private:
	bool mInitialized = false;
	psa_key_id_t mSecretKeyId = 0;
	K256PublicKey mPublicKey;
	size_t mPublicKeySize = sizeof(K256PublicKey);
};

} // namespace ECDSA_Test
```

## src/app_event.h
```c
/*
 * Copyright (c) 2021 Nordic Semiconductor ASA
 *
 * SPDX-License-Identifier: LicenseRef-Nordic-5-Clause
 */

#pragma once

#include <cstdint>

#include "event_types.h"

class LEDWidget;

enum class AppEventType : uint8_t { None = 0, Button, ButtonPushed, ButtonReleased, Timer, UpdateLedState };

enum class FunctionEvent : uint8_t { NoneSelected = 0, SoftwareUpdate = 0, FactoryReset };

struct AppEvent {
	union {
		struct {
			uint8_t PinNo;
			uint8_t Action;
		} ButtonEvent;
		struct {
			void *Context;
		} TimerEvent;
		struct {
			LEDWidget *LedWidget;
		} UpdateLedStateEvent;
	};

	AppEventType Type{ AppEventType::None };
	EventHandler Handler;
};
```

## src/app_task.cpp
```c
/*
 * Copyright (c) 2021 Nordic Semiconductor ASA
 *
 * SPDX-License-Identifier: LicenseRef-Nordic-5-Clause
 */

#include "app_task.h"

#include "app/matter_init.h"
#include "app/task_executor.h"
#include "board/board.h"

#ifdef CONFIG_CHIP_OTA_REQUESTOR
#include "dfu/ota/ota_util.h"
#endif

/*----------------------------------------------------------
ECDSA signing with secp256k1 TEST
-----------------------------------------------------------*/
#ifdef CONFIG_ECDSA_SECP256K1_TEST
#include "ECDSA_secp256k1.h"
#endif
/*----------------------------------------------------------
END
-----------------------------------------------------------*/

#include <app/server/OnboardingCodesUtil.h>

#include <zephyr/logging/log.h>

LOG_MODULE_DECLARE(app, CONFIG_CHIP_APP_LOG_LEVEL);

using namespace ::chip;
using namespace ::chip::app;
using namespace ::chip::DeviceLayer;

CHIP_ERROR AppTask::Init()
{
	/* Initialize Matter stack */
	ReturnErrorOnFailure(Nrf::Matter::PrepareServer());

	if (!Nrf::GetBoard().Init()) {
		LOG_ERR("User interface initialization failed.");
		return CHIP_ERROR_INCORRECT_STATE;
	}

	/* Register Matter event handler that controls the connectivity status LED based on the captured Matter network
	 * state. */
	ReturnErrorOnFailure(Nrf::Matter::RegisterEventHandler(Nrf::Board::DefaultMatterEventHandler, 0));

	return Nrf::Matter::StartServer();
}

CHIP_ERROR AppTask::StartApp()
{
	ReturnErrorOnFailure(Init());

	/*----------------------------------------------------------
	ECDSA signing with secp256k1 TEST
	-----------------------------------------------------------*/
#ifdef CONFIG_ECDSA_SECP256K1_TEST

	psa_status_t status = PSA_SUCCESS;

	{
		LOG_ERR("\n\nECDSA SECP256K1 TEST\n\n");
		ECDSA_Test::K256Keypair keyPair;

		LOG_INF("Initializing Keypair...");
		status = keyPair.Initialize();
		if (PSA_SUCCESS != status) {
			LOG_ERR("Failed %d\n", status);
		} else {
			LOG_INF("Success!\n");
		}

		LOG_INF("Signing a message...");
		ECDSA_Test::K256ECDSASignature signature;
		status = keyPair.ECDSA_sign_msg(ECDSA_Test::kTestMessage, sizeof(ECDSA_Test::kTestMessage), signature);
		if (PSA_SUCCESS != status) {
			LOG_ERR("Failed %d\n", status);
		} else {
			LOG_INF("Success!\n");
		}

		LOG_INF("Validating message signature...");
		ECDSA_Test::K256PublicKey testPubKey;
		memcpy(testPubKey, keyPair.GetPubKey(), keyPair.GetPubKeyLen());
		status = keyPair.ECDSA_validate_msg_signature(ECDSA_Test::kTestMessage,
							      sizeof(ECDSA_Test::kTestMessage), signature, testPubKey);
		if (PSA_SUCCESS != status) {
			LOG_ERR("Failed %d\n", status);
		} else {
			LOG_INF("Success!\n");
		}
	}

	{
		LOG_INF("Testing with known keys generated externally using OpenSSL\n");

		ECDSA_Test::K256Keypair keyPair;

		LOG_INF("Importing keypair...");
		status = keyPair.Import(ECDSA_Test::kTestPrivKey, sizeof(ECDSA_Test::kTestPrivKey),
					ECDSA_Test::kTestPubKey, sizeof(ECDSA_Test::kTestPubKey));
		if (PSA_SUCCESS != status) {
			LOG_ERR("Failed %d\n", status);
		} else {
			LOG_INF("Success!\n");
		}

		LOG_INF("Comparing Public Key...");
		if (memcmp(ECDSA_Test::kTestPubKey, keyPair.GetPubKey(), keyPair.GetPubKeyLen()) != 0) {
			LOG_ERR("Failed\n");
		} else {
			LOG_INF("Success!\n");
		}

		uint8_t exportedPrivKey[ECDSA_Test::kK256_PrivateKeyLength];
		size_t exportedSizeLen = sizeof(exportedPrivKey);
		LOG_INF("Exporting Private Key...");
#ifdef CONFIG_ECDSA_SECP256K1_TEST_ALLOW_KEY_EXPORT
		status = keyPair.Export(exportedPrivKey, exportedSizeLen);
		if (PSA_SUCCESS != status) {
			LOG_ERR("Failed %d\n", status);
		} else {
			LOG_INF("Success!\n");
		}

		LOG_INF("Comparing Private Keys...");
		if (memcmp(exportedPrivKey, ECDSA_Test::kTestPrivKey, ECDSA_Test::kK256_PrivateKeyLength) != 0) {
			LOG_ERR("Failed\n");
		} else {
			LOG_INF("Success!\n");
		}
#else
		status = keyPair.Export(exportedPrivKey, exportedSizeLen);
		if (PSA_SUCCESS == status) {
			LOG_ERR("ECDSA SECP256K1 Export keypair should fail but got success");
		} else {
			LOG_INF("Success!\n");
		}
#endif

		LOG_INF("Signing a message...");
		ECDSA_Test::K256ECDSASignature signature = {};
		auto signingTimeStart = System::SystemClock().GetMonotonicTimestamp();
		status = keyPair.ECDSA_sign_msg(ECDSA_Test::kTestMessage, sizeof(ECDSA_Test::kTestMessage), signature);
		auto signingTimeEnd = System::SystemClock().GetMonotonicTimestamp();
		if (PSA_SUCCESS != status) {
			LOG_ERR("Failed %d\n", status);
		} else {
			LOG_INF("Success!\n");
		}

		LOG_INF("Validating message signature...");
		ECDSA_Test::K256PublicKey pubKey;
		memcpy(pubKey, ECDSA_Test::kTestPubKey, sizeof(pubKey));
		auto validationTimeStart = System::SystemClock().GetMonotonicTimestamp();
		status = keyPair.ECDSA_validate_msg_signature(ECDSA_Test::kTestMessage,
							      sizeof(ECDSA_Test::kTestMessage), signature, pubKey);
		auto validationTimeEnd = System::SystemClock().GetMonotonicTimestamp();
		if (PSA_SUCCESS != status) {
			LOG_ERR("Failed %d\n", status);
		} else {
			LOG_INF("Success!\n");
		}

		LOG_INF("ECDSA SECP256K1 signing time: %llu ms",
			validationTimeEnd.count() - validationTimeStart.count());
		LOG_INF("ECDSA SECP256K1 validating time: %llu ms", signingTimeEnd.count() - signingTimeStart.count());
	}

	LOG_INF("\n\nECDSA SECP256K1 TEST FINISHED\n\n");
#endif
	/*----------------------------------------------------------
	END
	-----------------------------------------------------------*/

	while (true) {
		Nrf::DispatchNextTask();
	}

	return CHIP_NO_ERROR;
}
```

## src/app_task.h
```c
/*
 * Copyright (c) 2021 Nordic Semiconductor ASA
 *
 * SPDX-License-Identifier: LicenseRef-Nordic-5-Clause
 */

#pragma once

#include "app_event.h"
#include "led_widget.h"

#include <platform/CHIPDeviceLayer.h>

#if CONFIG_CHIP_FACTORY_DATA
#include <platform/nrfconnect/FactoryDataProvider.h>
#else
#include <platform/nrfconnect/DeviceInstanceInfoProviderImpl.h>
#endif

#ifdef CONFIG_MCUMGR_TRANSPORT_BT
#include "dfu_over_smp.h"
#endif

struct k_timer;

class AppTask {
public:

	static AppTask &Instance()
	{
		static AppTask sAppTask;
		return sAppTask;
	};

	CHIP_ERROR StartApp();

	static void PostEvent(const AppEvent &event);

private:
	CHIP_ERROR Init();

	void CancelTimer();
	void StartTimer(uint32_t timeoutInMs);

	static void DispatchEvent(const AppEvent &event);
	static void UpdateLedStateEventHandler(const AppEvent &event);
	static void FunctionHandler(const AppEvent &event);
	static void FunctionTimerEventHandler(const AppEvent &event);

	static void ChipEventHandler(const chip::DeviceLayer::ChipDeviceEvent *event, intptr_t arg);
	static void ButtonEventHandler(uint32_t buttonState, uint32_t hasChanged);
	static void LEDStateUpdateHandler(LEDWidget &ledWidget);
	static void FunctionTimerTimeoutCallback(k_timer *timer);
	static void UpdateStatusLED();

	FunctionEvent mFunction = FunctionEvent::NoneSelected;
	bool mFunctionTimerActive = false;

#if CONFIG_CHIP_FACTORY_DATA
	chip::DeviceLayer::FactoryDataProvider<chip::DeviceLayer::InternalFlashFactoryData> mFactoryDataProvider;
#endif
};
```

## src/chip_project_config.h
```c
/*
 * Copyright (c) 2021 Nordic Semiconductor ASA
 *
 * SPDX-License-Identifier: LicenseRef-Nordic-5-Clause
 */

/**
 *    @file
 *          Example project configuration file for CHIP.
 *
 *          This is a place to put application or project-specific overrides
 *          to the default configuration values for general CHIP features.
 *
 */

#pragma once

#define CHIP_CONFIG_LOG_MODULE_Zcl_PROGRESS 0
#define CHIP_CONFIG_LOG_MODULE_InteractionModel_PROGRESS 0
#define CHIP_CONFIG_LOG_MODULE_InteractionModel_DETAIL 0
#define CHIP_CONFIG_LOG_MODULE_DataManagement_PROGRESS 0
#define CHIP_CONFIG_LOG_MODULE_FabricProvisioning_PROGRESS 0
#define CHIP_CONFIG_LOG_MODULE_SecureChannel_PROGRESS 0
```
